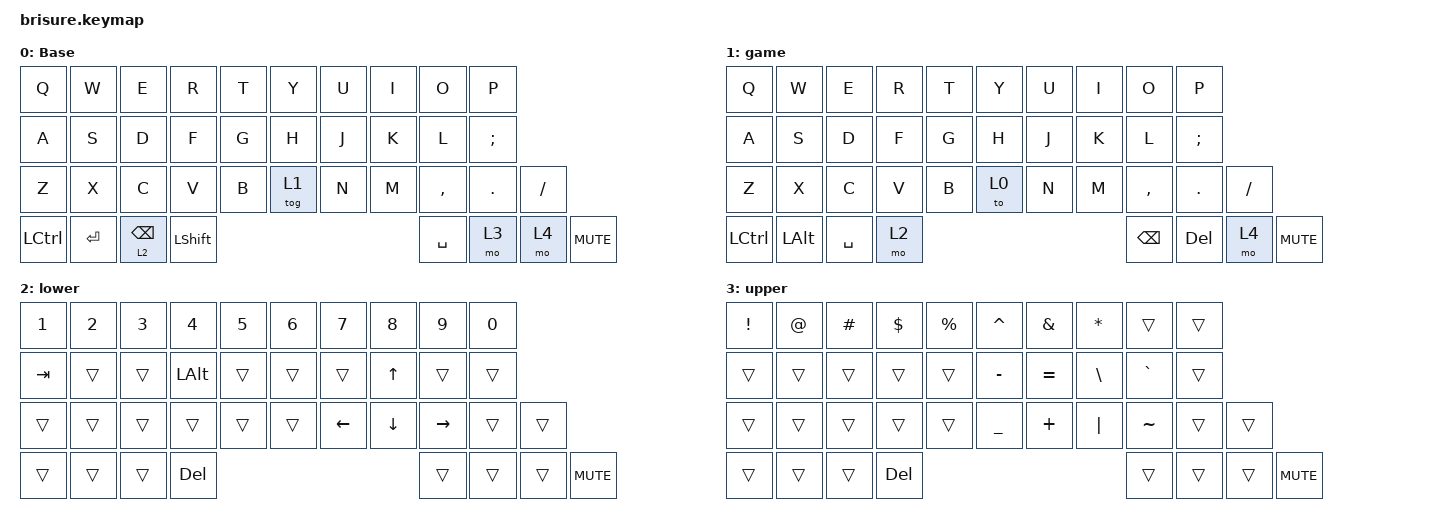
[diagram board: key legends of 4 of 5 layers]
#include <behaviors.dtsi>
#include <dt-bindings/zmk/keys.h>

/ {
    behaviors {
        hrm: HRM {
            compatible = "zmk,behavior-hold-tap";
            label = "HRM";
            #binding-cells = <2>;
            flavor = "balanced";
            tapping-term-ms = <280>;
            quick-tap-ms = <175>;
            require-prior-idle-ms = <150>;
            bindings = <&kp>, <&kp>;

            hold-trigger-key-positions = < 0 1 2 3 4 5 6 7 8 9 10 11 12 13 14 15 16 17 18 19 20 21 22 23 24 25 26 27 28 29 30 31 32 33>;
            hold-trigger-on-release;
        };
    };

    combos {
        compatible = "zmk,combos";

        par1 {
            bindings = <&kp LEFT_PARENTHESIS>;
            key-positions = <3 2>;
            layers = <0>;
        };

        par2 {
            bindings = <&kp RIGHT_PARENTHESIS>;
            key-positions = <6 7>;
            layers = <0>;
        };

        cur1 {
            bindings = <&kp LEFT_BRACE>;
            key-positions = <23 22>;
            layers = <0>;
        };

        cur2 {
            bindings = <&kp RIGHT_BRACE>;
            key-positions = <26 27>;
            layers = <0>;
        };

        bracket1 {
            bindings = <&kp LEFT_BRACKET>;
            key-positions = <13 12>;
            layers = <0>;
        };

        bracket2 {
            bindings = <&kp RIGHT_BRACKET>;
            key-positions = <16 17>;
            layers = <0>;
        };

        esc {
            bindings = <&kp ESCAPE>;
            key-positions = <1 0>;
            layers = <0 1>;
        };

        quotes {
            bindings = <&kp SINGLE_QUOTE>;
            key-positions = <18 19>;
            layers = <0>;
        };

        enter {
            bindings = <&kp ENTER>;
            key-positions = <16 17 18>;
            layers = <0>;
        };

        lower {
            bindings = <&mo 1>;
            key-positions = <26 27 28>;
            layers = <0>;
        };

        shift {
            bindings = <&kp LEFT_SHIFT>;
            key-positions = <11 13 12>;
            layers = <0>;
        };

        alt {
            bindings = <&kp LALT>;
            key-positions = <21 22 23>;
            layers = <0>;
        };

        gui {
            bindings = <&kp LGUI>;
            key-positions = <31 32>;
            layers = <0 1>;
        };

    };

    keymap {
        compatible = "zmk,keymap";

        base {
            display-name = "Base";
            bindings = <
&kp Q      &kp W     &kp E  &kp R      &kp T  &kp Y   &kp U      &kp I  &kp O      &kp P
&kp A      &kp S     &kp D  &kp F      &kp G  &kp H   &kp J      &kp K  &kp L      &kp SEMI            
&kp Z      &kp X     &kp C  &kp V      &kp B  &tog 1  &kp N      &kp M  &kp COMMA  &kp DOT   &kp FSLH
&kp LCTRL  &kp ENTER       &lt 2 BSPC         &kp LEFT_SHIFT   &kp SPACE         &mo 3      &mo 4 &kp C_MUTE
            >;

            sensor-bindings = <&inc_dec_kp C_VOL_UP C_VOL_DN>;
        };
        game {
            display-name = "game";
            bindings = <
&kp Q      &kp W     &kp E  &kp R      &kp T  &kp Y   &kp U      &kp I  &kp O      &kp P
&kp A      &kp S     &kp D  &kp F      &kp G  &kp H   &kp J      &kp K  &kp L      &kp SEMI         
&kp Z      &kp X     &kp C  &kp V      &kp B  &to 0  &kp N      &kp M  &kp COMMA  &kp DOT   &kp FSLH
&kp LCTRL  &kp LALT         &kp SPACE         &mo 2   &kp BSPC         &kp DEL      &mo 4 &kp C_MUTE
            >;

            sensor-bindings = <&inc_dec_kp C_VOL_UP C_VOL_DN>;
        };

        lower {
            bindings = <
&kp N1   &kp N2  &kp N3  &kp N4  &kp N5         &kp N6  &kp N7  &kp N8   &kp N9   &kp N0
&kp TAB  &trans  &trans  &kp LALT  &trans          &trans  &trans  &kp UP   &trans   &trans         
&trans   &trans  &trans  &trans &trans          &trans   &kp LEFT &kp DOWN  &kp RIGHT  &trans     &trans  
&trans   &trans          &trans                  &kp DEL    &trans          &trans     &trans     &kp C_MUTE
            >;

            sensor-bindings = <&inc_dec_kp C_VOL_UP C_VOL_DN>;
        };

        upper {
            bindings = <
&kp EXCL  &kp AT  &kp HASH  &kp DOLLAR  &kp PERCENT  &kp CARET  &kp AMPS  &kp STAR  &trans  &trans
&trans  &trans  &trans  &trans &trans     &kp MINUS  &kp EQUAL  &kp BSLH   &kp GRAVE  &trans         
&trans   &trans  &trans  &trans &trans        &kp UNDER  &kp PLUS   &kp PIPE   &kp TILDE       &trans  &trans
&trans   &trans          &trans                   &kp DEL    &trans                &trans     &trans &kp C_MUTE
            >;
            sensor-bindings = <&inc_dec_kp C_VOL_UP C_VOL_DN>;
        };

        fn-bootloader {
            bindings = <
&kp F1   &kp F2   &kp F3  &kp F4  &kp F5       &kp F6  &kp F7  &kp F8  &kp F9  &kp F10
&kp F11  &kp F12  &trans  &trans  &bootloader  &trans  &trans  &trans  &trans  &trans           &trans
&trans   &trans   &trans  &trans  &trans       &trans  &trans  &trans  &trans  &trans   &trans
&trans   &trans           &trans               &trans  &trans          &trans  &trans &kp C_MUTE
            >;
            sensor-bindings = <&inc_dec_kp C_VOL_UP C_VOL_DN>;
        };
    };
};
